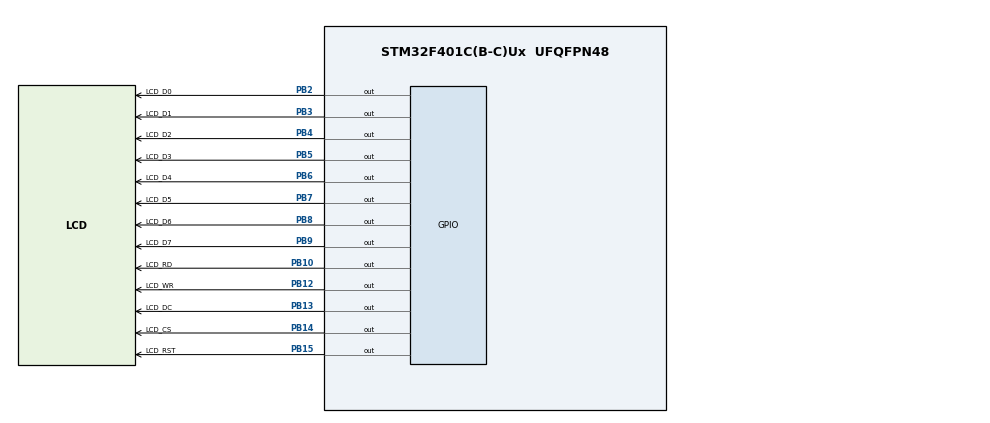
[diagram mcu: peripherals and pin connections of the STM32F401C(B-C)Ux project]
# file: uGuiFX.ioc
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ADC1.Channel-2\#ChannelRegularConversion=ADC_CHANNEL_VBAT
ADC1.NbrOfConversionFlag=1
ADC1.Rank-2\#ChannelRegularConversion=1
ADC1.SamplingTime-2\#ChannelRegularConversion=ADC_SAMPLETIME_3CYCLES
ADC1.master=1
Mcu.Family=STM32F4
Mcu.Name=STM32F401C(B-C)Ux
Mcu.Package=UFQFPN48
NVIC.PriorityGroup=NVIC_PRIORITYGROUP_4
PA13.Mode=Serial_Wire
PA13.Signal=SYS_JTMS-SWDIO
PA14.Mode=Serial_Wire
PA14.Signal=SYS_JTCK-SWCLK
PB10.GPIO_Label=LCD_RD
PB10.GPIO_ModeDefaultOutputPP=GPIO_MODE_OUTPUT_PP
PB10.GPIO_PuPd=GPIO_NOPULL
PB10.GPIO_Speed=GPIO_SPEED_FREQ_VERY_HIGH
PB10.PinState=GPIO_PIN_RESET
PB10.Signal=GPIO_Output
PB12.GPIO_Label=LCD_WR
PB12.GPIO_ModeDefaultOutputPP=GPIO_MODE_OUTPUT_PP
PB12.GPIO_PuPd=GPIO_NOPULL
PB12.GPIO_Speed=GPIO_SPEED_FREQ_VERY_HIGH
PB12.PinState=GPIO_PIN_RESET
PB12.Signal=GPIO_Output
PB13.GPIO_Label=LCD_DC
PB13.GPIO_ModeDefaultOutputPP=GPIO_MODE_OUTPUT_PP
PB13.GPIO_PuPd=GPIO_NOPULL
PB13.GPIO_Speed=GPIO_SPEED_FREQ_VERY_HIGH
PB13.PinState=GPIO_PIN_RESET
PB13.Signal=GPIO_Output
PB14.GPIO_Label=LCD_CS
PB14.GPIO_ModeDefaultOutputPP=GPIO_MODE_OUTPUT_PP
PB14.GPIO_PuPd=GPIO_NOPULL
PB14.GPIO_Speed=GPIO_SPEED_FREQ_VERY_HIGH
PB14.PinState=GPIO_PIN_RESET
PB14.Signal=GPIO_Output
PB15.GPIO_Label=LCD_RST
PB15.GPIO_ModeDefaultOutputPP=GPIO_MODE_OUTPUT_PP
PB15.GPIO_PuPd=GPIO_NOPULL
PB15.GPIO_Speed=GPIO_SPEED_FREQ_VERY_HIGH
PB15.PinState=GPIO_PIN_RESET
PB15.Signal=GPIO_Output
PB2.GPIO_Label=LCD_D0
PB2.GPIO_ModeDefaultOutputPP=GPIO_MODE_OUTPUT_PP
PB2.GPIO_PuPd=GPIO_NOPULL
PB2.GPIO_Speed=GPIO_SPEED_FREQ_VERY_HIGH
PB2.PinState=GPIO_PIN_RESET
PB2.Signal=GPIO_Output
PB3.GPIO_Label=LCD_D1
PB3.GPIO_ModeDefaultOutputPP=GPIO_MODE_OUTPUT_PP
PB3.GPIO_PuPd=GPIO_NOPULL
PB3.GPIO_Speed=GPIO_SPEED_FREQ_VERY_HIGH
PB3.PinState=GPIO_PIN_RESET
PB3.Signal=GPIO_Output
PB4.GPIO_Label=LCD_D2
PB4.GPIO_ModeDefaultOutputPP=GPIO_MODE_OUTPUT_PP
PB4.GPIO_PuPd=GPIO_NOPULL
PB4.GPIO_Speed=GPIO_SPEED_FREQ_VERY_HIGH
PB4.PinState=GPIO_PIN_RESET
PB4.Signal=GPIO_Output
PB5.GPIO_Label=LCD_D3
PB5.GPIO_ModeDefaultOutputPP=GPIO_MODE_OUTPUT_PP
PB5.GPIO_PuPd=GPIO_NOPULL
PB5.GPIO_Speed=GPIO_SPEED_FREQ_VERY_HIGH
PB5.PinState=GPIO_PIN_RESET
PB5.Signal=GPIO_Output
PB6.GPIO_Label=LCD_D4
PB6.GPIO_ModeDefaultOutputPP=GPIO_MODE_OUTPUT_PP
PB6.GPIO_PuPd=GPIO_NOPULL
PB6.GPIO_Speed=GPIO_SPEED_FREQ_VERY_HIGH
PB6.PinState=GPIO_PIN_RESET
PB6.Signal=GPIO_Output
PB7.GPIO_Label=LCD_D5
PB7.GPIO_ModeDefaultOutputPP=GPIO_MODE_OUTPUT_PP
PB7.GPIO_PuPd=GPIO_NOPULL
PB7.GPIO_Speed=GPIO_SPEED_FREQ_VERY_HIGH
PB7.PinState=GPIO_PIN_RESET
PB7.Signal=GPIO_Output
PB8.GPIO_Label=LCD_D6
PB8.GPIO_ModeDefaultOutputPP=GPIO_MODE_OUTPUT_PP
PB8.GPIO_PuPd=GPIO_NOPULL
PB8.GPIO_Speed=GPIO_SPEED_FREQ_VERY_HIGH
PB8.PinState=GPIO_PIN_RESET
PB8.Signal=GPIO_Output
PB9.GPIO_Label=LCD_D7
PB9.GPIO_ModeDefaultOutputPP=GPIO_MODE_OUTPUT_PP
PB9.GPIO_PuPd=GPIO_NOPULL
PB9.GPIO_Speed=GPIO_SPEED_FREQ_VERY_HIGH
PB9.PinState=GPIO_PIN_RESET
PB9.Signal=GPIO_Output
PC14-OSC32_IN.Mode=LSE-External-Oscillator
PC14-OSC32_IN.Signal=RCC_OSC32_IN
PC15-OSC32_OUT.Mode=LSE-External-Oscillator
PC15-OSC32_OUT.Signal=RCC_OSC32_OUT
ProjectManager.HeapSize=0x200
ProjectManager.StackSize=0x400
ProjectManager.TargetToolchain=Makefile
RCC.48MHZClocksFreq_Value=25000000
RCC.AHBCLKDivider=RCC_SYSCLK_DIV8
RCC.AHBFreq_Value=6250000
RCC.APB1CLKDivider=RCC_HCLK_DIV2
RCC.APB1Freq_Value=3125000
RCC.APB1TimFreq_Value=6250000
RCC.APB2Freq_Value=6250000
RCC.APB2TimFreq_Value=6250000
RCC.CortexFreq_Value=6250000
RCC.HCLKFreq_Value=6250000
RCC.HSE_VALUE=25000000
RCC.HSI_VALUE=16000000
RCC.PLLM=8
RCC.PLLN=50
RCC.SYSCLKFreq_VALUE=50000000
RCC.SYSCLKSource=RCC_SYSCLKSOURCE_PLLCLK
RCC.VCOOutputFreq_Value=100000000
VP_ADC1_Vbat_Input.Mode=IN-Vbat
VP_ADC1_Vref_Input.Mode=IN-Vrefint
board=custom

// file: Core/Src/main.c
/* USER CODE BEGIN Header */
/**
  ******************************************************************************
  * @file           : main.c
  * @brief          : Main program body
  ******************************************************************************
  * @attention
  *
  * <h2><center>&copy; Copyright (c) 2020 STMicroelectronics.
  * All rights reserved.</center></h2>
  *
  * This software component is licensed by ST under BSD 3-Clause license,
  * the "License"; You may not use this file except in compliance with the
  * License. You may obtain a copy of the License at:
  *                        opensource.org/licenses/BSD-3-Clause
  *
  ******************************************************************************
  */
/* USER CODE END Header */
#include "main.h"
#include "adc.h"
#include "gpio.h"

/* USER CODE BEGIN Includes */

#include "example.h"

/* USER CODE END Includes */

void SystemClock_Config(void);

int main(void)
{

  /* MCU Configuration--------------------------------------------------------*/

  /* Reset of all peripherals, Initializes the Flash interface and the Systick. */

  LL_APB2_GRP1_EnableClock(LL_APB2_GRP1_PERIPH_SYSCFG);
  LL_APB1_GRP1_EnableClock(LL_APB1_GRP1_PERIPH_PWR);

  NVIC_SetPriorityGrouping(NVIC_PRIORITYGROUP_4);

  /* System interrupt init*/

  /* Configure the system clock */
  SystemClock_Config();

  /* Initialize all configured peripherals */
  MX_GPIO_Init();
  MX_ADC1_Init();
  /* USER CODE BEGIN 2 */
  Display_Init();
  // Touch_ADC_Init();
  begin();
  /* USER CODE END 2 */

  /* Infinite loop */
  while (1)
  {

    /* USER CODE BEGIN 3 */

    loop();
  }
  /* USER CODE END 3 */
}

void SystemClock_Config(void)
{
  LL_FLASH_SetLatency(LL_FLASH_LATENCY_0);
  while(LL_FLASH_GetLatency()!= LL_FLASH_LATENCY_0)
  {
  }
  LL_PWR_SetRegulVoltageScaling(LL_PWR_REGU_VOLTAGE_SCALE2);
  LL_RCC_HSI_SetCalibTrimming(16);
  LL_RCC_HSI_Enable();

   /* Wait till HSI is ready */
  while(LL_RCC_HSI_IsReady() != 1)
  {

  }
  LL_RCC_PLL_ConfigDomain_SYS(LL_RCC_PLLSOURCE_HSI, LL_RCC_PLLM_DIV_8, 50, LL_RCC_PLLP_DIV_2);
  LL_RCC_PLL_Enable();

   /* Wait till PLL is ready */
  while(LL_RCC_PLL_IsReady() != 1)
  {

  }
  LL_RCC_SetAHBPrescaler(LL_RCC_SYSCLK_DIV_8);
  LL_RCC_SetAPB1Prescaler(LL_RCC_APB1_DIV_2);
  LL_RCC_SetAPB2Prescaler(LL_RCC_APB2_DIV_1);
  LL_RCC_SetSysClkSource(LL_RCC_SYS_CLKSOURCE_PLL);

   /* Wait till System clock is ready */
  while(LL_RCC_GetSysClkSource() != LL_RCC_SYS_CLKSOURCE_STATUS_PLL)
  {

  }
  LL_Init1msTick(6250000);
  LL_SetSystemCoreClock(6250000);
  LL_RCC_SetTIMPrescaler(LL_RCC_TIM_PRESCALER_TWICE);
}

void Error_Handler(void)
{
}

/************************ (C) COPYRIGHT STMicroelectronics *****END OF FILE****/
